AUTOSAR XML (schema 4-2-2)
standard types defined: boolean, float32, sint16, sint32, sint8, uint16, uint32, uint8
package /Communication/DataTransformation
  data transformation set TransformerChains
    data transformation TransformerChain_E2E_only: execute-despite-data-unavailability=true, transformer-chain=E2E_Transformer
    data transformation TransformerChain_SOME_IP_E2E: execute-despite-data-unavailability=true, transformer-chain=[SOME_IP_Transformer, E2E_Transformer]
    data transformation TransformerChain_SOME_IP_only: execute-despite-data-unavailability=true, transformer-chain=SOME_IP_Transformer
  data transformation set Transformers
    transformation technology E2E_Transformer: needs-original-data=false, protocol=E2E, transformer-class=SAFETY, version=1
    transformation technology SOME_IP_Transformer: protocol=SOMEIP, someip-transformation-description{alignment=8, byte-order=big-endian, interface-version=1}, transformer-class=SERIALIZER, version=1
package /Communication/Diagnostics
  diagnostic connection DoIP_MyECU: functional-request=DoIP_Conn_funct, physical-request=DoIP_Conn_MyECU_Physical_Request, response=DoIP_Conn_MyECU_Response
  diagnostic connection DoIP_MyECU_Flasher: functional-request=DoIP_Conn_funct_Flasher, physical-request=DoIP_Conn_MyECU_Physical_Request_Flasher, response=DoIP_Conn_MyECU_Response_Flasher
package /Communication/GlobalTimeSynchronization
  global time domain GlobalTimeDomain: communication-cluster=ETHCluster
    global time eth master MyECU_ETH_GlobalTimeMaster: communication-connector=MyECU_EEI_U, is-system-wide-global-time-master=true, sync-period=0.125
package /Communication/NetworkManagement
  nm config NM_CONFIG: udp-nm-cluster-coupling=coupled-cluster=NM_Cluster
    udp nm cluster NM_Cluster: communication-cluster=ETHCluster, nm-channel-id=48, nm-channel-active=true, nm-message-timeout-time=0.06, nm-msg-cycle-time=0.1, nm-network-timeout=1, nm-nid-position=1, nm-remote-sleep-indication-time=0.5, nm-repeat-message-time=0.4, nm-user-data-length=6, nm-wait-bus-sleep-time=0.75
      udp nm node MyECU_NM_Node: controller=BA_MyECU_0_EPC, nm-if-ecu=MyECU_NM_ECU, rx-nm-pdu=PDU_UdpNmRX_MyECU, tx-nm-pdu=PDU_UdpNmTx_MyECU
    nm-if-ecus:
      nm ecu MyECU_NM_ECU: ecu-instance=MyECU, nm-com-control-enabled=true, nm-node-id-enabled=true, nm-passive-mode-enabled=false, nm-user-data-enabled=true
package /Communication/PDUs
  dcm i pdu DoIP_MyECU_Physical_Request_Tester_MyECU: length=188
  dcm i pdu DoIP_MyECU_Physical_Request_Tester_MyECU_Flasher: length=188
  dcm i pdu DoIP_MyECU_Response_MyECU_Tester: length=188
  dcm i pdu DoIP_MyECU_Response_MyECU_Tester_Flasher: length=188
  dcm i pdu DoIP_Functional_Request_DoIP_Flasher: length=188
  dcm i pdu DoIP_Functional_Request_all_nodes: length=188
  general purpose pdu DoIP_TCP01_MyECU_Tx_Tester_Rx: category=DoIP, length=8
  general purpose pdu DoIP_TCP01_Tester_Tx_MyECU_Rx: category=DoIP, length=8
  general purpose pdu DoIP_TCP02_MyECU_Tx_Tester_Rx: category=DoIP, length=8
  general purpose pdu DoIP_TCP02_Tester_Tx_MyECU_Rx: category=DoIP, length=8
  general purpose pdu DoIP_UDP_MyECU_Tx_Tester_Rx: category=DoIP, length=8
  general purpose pdu DoIP_UDP_Tester_Tx_MyECU_Rx: category=DoIP, length=8
  general purpose pdu DoIP_UDP_VehicleAnnouncement: category=DoIP, length=8
  general purpose pdu SD_Ctrl_Rx: category=SD, length=1500
  general purpose pdu SD_Ctrl_Rx_Multicast: category=SD, length=1500
  general purpose pdu SD_Ctrl_Tx: category=SD, length=1500
  pdu Basics_Echo_Dashboard: length=12, transmission-mode-true-timing=event-controlled-timing=number-of-repetitions=0, unused-bit-pattern=0
    signal Basics_Echo_Dashboard: start 0, 96 bit, opaque, data-transformations=TransformerChain_SOME_IP_only, data-type-policy=OVERRIDE, base-type=LdCom_UINT8_N, someip-transformation-i-signal-props=SOME_IP_Transformer, transfer-property=TRIGGERED, to MyECU
  pdu Maths_Add_call_Dashboard: length=16, transmission-mode-true-timing=event-controlled-timing=number-of-repetitions=0, unused-bit-pattern=0
    signal Maths_Add_call_Dashboard: start 0, 128 bit, opaque, data-transformations=TransformerChain_SOME_IP_only, data-type-policy=OVERRIDE, base-type=LdCom_UINT8_N, someip-transformation-i-signal-props=SOME_IP_Transformer, transfer-property=TRIGGERED, to MyECU
  pdu Maths_Add_return_MyECU: length=12, transmission-mode-true-timing=event-controlled-timing=number-of-repetitions=0, unused-bit-pattern=0
    signal Maths_Add_return_MyECU: start 0, 96 bit, opaque, data-transformations=TransformerChain_SOME_IP_only, data-type-policy=OVERRIDE, base-type=LdCom_UINT8_N, someip-transformation-i-signal-props=SOME_IP_Transformer, transfer-property=TRIGGERED
  pdu Maths_Divide_call_Dashboard: length=16, transmission-mode-true-timing=event-controlled-timing=number-of-repetitions=0, unused-bit-pattern=0
    signal Maths_Divide_call_Dashboard: start 0, 128 bit, opaque, data-transformations=TransformerChain_SOME_IP_only, data-type-policy=OVERRIDE, base-type=LdCom_UINT8_N, someip-transformation-i-signal-props=SOME_IP_Transformer, transfer-property=TRIGGERED, to MyECU
  pdu Maths_Divide_return_MyECU: length=12, transmission-mode-true-timing=event-controlled-timing=number-of-repetitions=0, unused-bit-pattern=0
    signal Maths_Divide_return_MyECU: start 0, 96 bit, opaque, data-transformations=TransformerChain_SOME_IP_only, data-type-policy=OVERRIDE, base-type=LdCom_UINT8_N, someip-transformation-i-signal-props=SOME_IP_Transformer, transfer-property=TRIGGERED
  pdu Maths_Multiply_call_Dashboard: length=16, transmission-mode-true-timing=event-controlled-timing=number-of-repetitions=0, unused-bit-pattern=0
    signal Maths_Multiply_call_Dashboard: start 0, 128 bit, opaque, data-transformations=TransformerChain_SOME_IP_only, data-type-policy=OVERRIDE, base-type=LdCom_UINT8_N, someip-transformation-i-signal-props=SOME_IP_Transformer, transfer-property=TRIGGERED, to MyECU
  pdu Maths_Multiply_return_MyECU: length=12, transmission-mode-true-timing=event-controlled-timing=number-of-repetitions=0, unused-bit-pattern=0
    signal Maths_Multiply_return_MyECU: start 0, 96 bit, opaque, data-transformations=TransformerChain_SOME_IP_only, data-type-policy=OVERRIDE, base-type=LdCom_UINT8_N, someip-transformation-i-signal-props=SOME_IP_Transformer, transfer-property=TRIGGERED
  pdu Maths_Substract_call_Dashboard: length=16, transmission-mode-true-timing=event-controlled-timing=number-of-repetitions=0, unused-bit-pattern=0
    signal Maths_Substract_call_Dashboard: start 0, 128 bit, opaque, data-transformations=TransformerChain_SOME_IP_only, data-type-policy=OVERRIDE, base-type=LdCom_UINT8_N, someip-transformation-i-signal-props=SOME_IP_Transformer, transfer-property=TRIGGERED, to MyECU
  pdu Maths_Substract_return_MyECU: length=12, transmission-mode-true-timing=event-controlled-timing=number-of-repetitions=0, unused-bit-pattern=0
    signal Maths_Substract_return_MyECU: start 0, 96 bit, opaque, data-transformations=TransformerChain_SOME_IP_only, data-type-policy=OVERRIDE, base-type=LdCom_UINT8_N, someip-transformation-i-signal-props=SOME_IP_Transformer, transfer-property=TRIGGERED
  pdu Maths_Triangle_MyECU: length=12, transmission-mode-true-timing=event-controlled-timing=number-of-repetitions=0, unused-bit-pattern=0
    signal Maths_Triangle_MyECU: start 0, 96 bit, opaque, data-transformations=TransformerChain_SOME_IP_only, data-type-policy=OVERRIDE, base-type=LdCom_UINT8_N, someip-transformation-i-signal-props{transformer=SOME_IP_Transformer, message-type=NOTIFICATION}, transfer-property=TRIGGERED
  nm pdu PDU_UdpNmRX_MyECU: length=8, nm-data-information=true  # NM_Dummy_ST3 | Network Management
    signal S_UdpNm_UserData_Rx_MyECU: start 16, 48 bit, opaque, system signal SS_UdpNm_UserData_Rx, data-type-policy=OVERRIDE, init-value=\0, base-type=uint8_6_iso_8859_1, transfer-property=PENDING
  nm pdu PDU_UdpNmTx_MyECU: length=8, nm-data-information=true  # NM_BC_F_ST3 | Network Management
    signal S_UdpNm_UserData_Tx_MyECU: start 16, 48 bit, opaque, system signal SS_UdpNm_UserData_Tx, data-type-policy=OVERRIDE, init-value=6 x 0, base-type=uint8_6_iso_8859_1, transfer-property=PENDING
  xcp pdu XCP_Request_PDU: length=16
  xcp pdu XCP_Response_PDU: length=128
package /Communication/SystemSignals
  9 x system signal:
    Maths_1_Add_call
    Maths_1_Add_return
    Maths_1_Divide_call
    Maths_1_Divide_return
    Maths_1_Multiply_call
    Maths_1_Multiply_return
    Maths_1_Substract_call
    Maths_1_Substract_return
    Maths_1_Triangle
package /Communication/TransportProtocol
  do ip tp config DoIPCfg: communication-cluster=ETHCluster
    6 x do ip logic address:
      DoIP_SA_Flasher: address=1
      DoIP_SA_Tester: address=409
      DoIP_TA_MyECU: address=512
      DoIP_TA_MyECU_Flash: address=512
      DoIP_TA_funct: address=58368
      DoIP_TA_funct_Flash: address=58368
    do-ip-tp-connection do-ip-source-address=DoIP_SA_Flasher, do-ip-target-address=DoIP_TA_MyECU_Flash, tp-sdu=DoIP_MyECU_Physical_Request_Tester_MyECU_Flasher:
      ident DoIP_Conn_MyECU_Physical_Request_Flasher
    do-ip-tp-connection do-ip-source-address=DoIP_SA_Flasher, do-ip-target-address=DoIP_TA_funct_Flash, tp-sdu=DoIP_Functional_Request_DoIP_Flasher:
      ident DoIP_Conn_funct_Flasher
    do-ip-tp-connection do-ip-source-address=DoIP_SA_Tester, do-ip-target-address=DoIP_TA_MyECU, tp-sdu=DoIP_MyECU_Physical_Request_Tester_MyECU:
      ident DoIP_Conn_MyECU_Physical_Request
    do-ip-tp-connection do-ip-source-address=DoIP_SA_Tester, do-ip-target-address=DoIP_TA_funct, tp-sdu=DoIP_Functional_Request_all_nodes:
      ident DoIP_Conn_funct
    do-ip-tp-connection do-ip-source-address=DoIP_TA_MyECU, do-ip-target-address=DoIP_SA_Tester, tp-sdu=DoIP_MyECU_Response_MyECU_Tester:
      ident DoIP_Conn_MyECU_Response
    do-ip-tp-connection do-ip-source-address=DoIP_TA_MyECU_Flash, do-ip-target-address=DoIP_SA_Flasher, tp-sdu=DoIP_MyECU_Response_MyECU_Tester_Flasher:
      ident DoIP_Conn_MyECU_Response_Flasher
package /Constants
  constant specification InitValue_0: value-spec=0 0 0 0 0 0
  constant specification initValue_Array_int: value-spec=[Lit1:0, Lit2:0, Lit3:0, Lit4:0, Lit5:0, Lit6:0]
package /DataTypeMappingSets
  data type mapping set Data_Type_Mappings
    data-type-maps:
      application-data-type=REC_Basics_1_0_Echo, implementation-data-type=REC_Basics_1_0_Echo
      application-data-type=REC_Maths_1_0_Triangle, implementation-data-type=REC_Maths_1_0_Triangle
      application-data-type=boolean_DT, implementation-data-type=boolean
      application-data-type=float32_DT, implementation-data-type=float32
      application-data-type=int16_DT, implementation-data-type=sint16
      application-data-type=int32_DT, implementation-data-type=sint32
      application-data-type=int8_DT, implementation-data-type=sint8
      application-data-type=uint16_DT, implementation-data-type=uint16
      application-data-type=uint8_DT, implementation-data-type=uint8
package /DataTypes/ApplicationDataTypes
  16 x app type:
    AdminDataTextType: category=STRING
    Boolean: category=BOOLEAN
    Opaque: category=opaque
    Reference: category=REFERENCE
    SOMEIP_ID: category=VALUE
    SOMEIP_ServiceID: category=VALUE
    String: category=STRING
    boolean_DT: category=VALUE
    float32_ADT_Basics: category=VALUE
    float32_ADT_Triangle: category=VALUE
    float32_DT: category=VALUE
    int16_DT: category=VALUE
    int32_DT: category=VALUE
    int8_DT: category=VALUE
    uint16_DT: category=VALUE
    uint8_DT: category=VALUE
  application record data type REC_Basics_1_0_Echo: category=STRUCTURE
    application record element value: category=VALUE, type=float32_ADT_Basics
  application record data type REC_Maths_1_0_Triangle: category=STRUCTURE
    application record element sample: category=VALUE, type=float32_ADT_Triangle
package /DataTypes/BaseTypes
  5 x base type, all with category=FIXED_LENGTH:
    LdCom_UINT8_N: base-type-size=8, base-type-encoding=NONE
    UdpNm_UINT8_N: base-type-size=8, base-type-encoding=NONE, byte-order=opaque
    uint32_1: base-type-size=32, base-type-encoding=NONE
    uint8_6_iso_8859_1: base-type-size=48, base-type-encoding=ISO-8859-1
    uint8_8_iso_8859_1: base-type-size=64, base-type-encoding=ISO-8859-1
package /DataTypes/CompuMethods
  compu method CM_sig_VitaReq_Ctrl: 0..4294967295=RANGE
  compu method CM_sig_VitaReq_Data: 0..4294967295=RANGE
  compu method CM_sig_VitaResp_Ctrl: 0..4294967295=RANGE
  compu method CM_sig_VitaResp_Data: 0..4294967295=RANGE
  compu method CM_sig_com_data1_CAN1: 0..18446744073709551615=RANGE
  compu method CM_sig_com_data1_CAN2: 0..18446744073709551615=RANGE
  compu method CM_sig_com_data2_CAN1: 0..18446744073709551615=RANGE
  compu method CM_sig_com_data2_CAN2: 0..18446744073709551615=RANGE
  compu method CM_sig_nm_MyECU_CAN1_UserData: 0..281474976710655=RANGE
  compu method CM_sig_nm_MyECU_CAN2_UserData: 0..281474976710655=RANGE
package /DataTypes/ImplementationDataTypes
  6 x impl type, all with category=STRUCTURE:
    REC_Basics_1_0_Echo
      element float32_Basics: category=VALUE, base-type=float32
    REC_BatteryWarning
      element boolean_BatteryWarning: category=VALUE, base-type=boolean, compu {0=FALSE, 1=TRUE}
    REC_Maths_1_0_Triangle
      element float32_Triangle: category=VALUE, base-type=float32
    REC_TurnIndicationSig
      element boolean_Turnindication: category=VALUE, base-type=boolean, compu {0=Blinker_OFF, 1=Blinker_ON}
    REC_Volume_1_0_CurrentFrequency
      element uint16_Frequency: category=VALUE, base-type=uint16
    REC_Volume_1_0_CurrentVolume
      element uint8_Volume: category=VALUE, base-type=uint8
package /SoAdRoutingGroups
  so ad routing group Basics_events: event-group-control-type=ACTIVATION-UNICAST
  so ad routing group Math_events: event-group-control-type=ACTIVATION-AND-TRIGGER-UNICAST
  so ad routing group Math_methods
package /SoftwareTypes/ComponentTypes
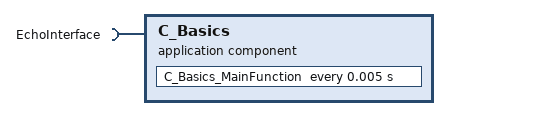
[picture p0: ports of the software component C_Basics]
  application sw component type C_Basics
    require port EchoInterface: nonqueued-receiver-com-spec{data-element=Echo, max-delta-counter-init=-1, filter=data-filter-type=ALWAYS, init-value=fields=0}, required-interface=EchoInterface
    behavior C_Basics_ib: data-type-mapping=Data_Type_Mappings
      timing event TMT_C_Basics_MainFunction: start-on-event=C_Basics_MainFunction, period=0.005
      runnable C_Basics_MainFunction
        data-receive-point-by-arguments:
          access REC_EchoInterface_Echo: accessed-variable=EchoInterface.Echo
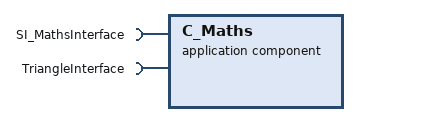
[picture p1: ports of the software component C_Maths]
  application sw component type C_Maths
    require port SI_MathsInterface: required-interface=SI_MathsInterface
    require port TriangleInterface: nonqueued-receiver-com-spec{data-element=Triangle, init-value=fields=0}, required-interface=TriangleInterface
    behavior C_Maths_ib: data-type-mapping=Data_Type_Mappings
  application sw component type P_Basics
    provide port EchoInterface: provided-interface=EchoInterface
    behavior P_Basics_ib: data-type-mapping=Data_Type_Mappings
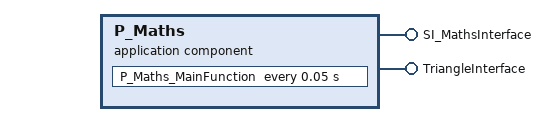
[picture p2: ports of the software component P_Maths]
  application sw component type P_Maths
    provide port SI_MathsInterface: provided-interface=SI_MathsInterface
      provided-com-specs:
        operation=Add, queue-length=1
        operation=Divide, queue-length=1
        operation=Multiply, queue-length=1
        operation=Substract, queue-length=1
    provide port TriangleInterface: nonqueued-sender-com-spec{data-element=Triangle, init-value=fields=0}, provided-interface=TriangleInterface
    behavior P_Maths_ib: data-type-mapping=Data_Type_Mappings
      4 x operation invoked event:
        OIT_P_Maths_SI_MathsInterface_Add_SI_MathsInterface_Add: start-on-event=P_Maths_SI_MathsInterface_Add, operation=SI_MathsInterface.Add
        OIT_P_Maths_SI_MathsInterface_Divide_SI_MathsInterface_Divide: start-on-event=P_Maths_SI_MathsInterface_Divide, operation=SI_MathsInterface.Divide
        OIT_P_Maths_SI_MathsInterface_Multiply_SI_MathsInterface_Multiply: start-on-event=P_Maths_SI_MathsInterface_Multiply, operation=SI_MathsInterface.Multiply
        OIT_P_Maths_SI_MathsInterface_Substract_SI_MathsInterface_Substract: start-on-event=P_Maths_SI_MathsInterface_Substract, operation=SI_MathsInterface.Substract
      timing event TMT_P_Maths_MainFunction: start-on-event=P_Maths_MainFunction, period=0.05
      5 x runnable:
        P_Maths_MainFunction
          data-send-points:
            access SEND_TriangleInterface_Triangle: accessed-variable=TriangleInterface.Triangle
        P_Maths_SI_MathsInterface_Add
        P_Maths_SI_MathsInterface_Divide
        P_Maths_SI_MathsInterface_Multiply
        P_Maths_SI_MathsInterface_Substract
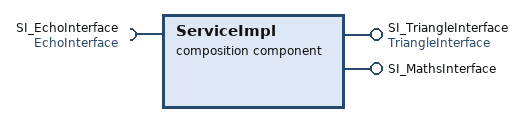
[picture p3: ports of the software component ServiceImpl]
  composition sw component type ServiceImpl
    require port SI_EchoInterface: nonqueued-receiver-com-spec{data-element=Echo, max-delta-counter-init=-1, filter=data-filter-type=ALWAYS}, required-interface=EchoInterface
    provide port SI_TriangleInterface: nonqueued-sender-com-spec=Triangle, provided-interface=TriangleInterface
    provide port SI_MathsInterface: provided-interface=SI_MathsInterface
      provided-com-specs:
        operation=Add, queue-length=1
        operation=Divide, queue-length=1
        operation=Multiply, queue-length=1
        operation=Substract, queue-length=1
    component C_Basics_MyECU: type=C_Basics
    component P_Maths_MyECU: type=P_Maths
    delegate P_Maths_MyECU.TriangleInterface <-> outer port ServiceImpl/SI_TriangleInterface
    delegate C_Basics_MyECU.EchoInterface <-> outer port ServiceImpl/SI_EchoInterface
    delegate P_Maths_MyECU.SI_MathsInterface <-> outer port ServiceImpl/SI_MathsInterface
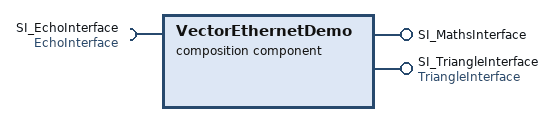
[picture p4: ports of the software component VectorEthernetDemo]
  composition sw component type VectorEthernetDemo
    provide port SI_MathsInterface: provided-interface=SI_MathsInterface
      provided-com-specs:
        operation=Add, queue-length=1
        operation=Divide, queue-length=1
        operation=Multiply, queue-length=1
        operation=Substract, queue-length=1
    provide port SI_TriangleInterface: nonqueued-sender-com-spec=Triangle, provided-interface=TriangleInterface
    require port SI_EchoInterface: nonqueued-receiver-com-spec{data-element=Echo, max-delta-counter-init=-1, filter=data-filter-type=ALWAYS}, required-interface=EchoInterface
    component ServiceImpl: type=ServiceImpl
    delegate ServiceImpl.SI_TriangleInterface <-> outer port VectorEthernetDemo/SI_TriangleInterface
    delegate ServiceImpl.SI_MathsInterface <-> outer port VectorEthernetDemo/SI_MathsInterface
    delegate ServiceImpl.SI_EchoInterface <-> outer port VectorEthernetDemo/SI_EchoInterface
package /SoftwareTypes/Interfaces
  client server interface SI_MathsInterface
    4 x operation:
      Add
        arg operand1: type=int32_DT, direction=IN, server-argument-impl-policy=USE-ARGUMENT-TYPE
        arg operand2: type=int32_DT, direction=IN, server-argument-impl-policy=USE-ARGUMENT-TYPE
        arg result: type=float32_DT, direction=OUT, server-argument-impl-policy=USE-ARGUMENT-TYPE
      Divide: possible-error=E_DIVISION_BY_ZERO
        arg operand1: type=int32_DT, direction=IN, server-argument-impl-policy=USE-ARGUMENT-TYPE
        arg operand2: type=int32_DT, direction=IN, server-argument-impl-policy=USE-ARGUMENT-TYPE
        arg result: type=float32_DT, direction=OUT, server-argument-impl-policy=USE-ARGUMENT-TYPE
      Multiply
        arg operand1: type=int32_DT, direction=IN, server-argument-impl-policy=USE-ARGUMENT-TYPE
        arg operand2: type=int32_DT, direction=IN, server-argument-impl-policy=USE-ARGUMENT-TYPE
        arg result: type=float32_DT, direction=OUT, server-argument-impl-policy=USE-ARGUMENT-TYPE
      Substract
        arg operand1: type=int32_DT, direction=IN, server-argument-impl-policy=USE-ARGUMENT-TYPE
        arg operand2: type=int32_DT, direction=IN, server-argument-impl-policy=USE-ARGUMENT-TYPE
        arg result: type=float32_DT, direction=OUT, server-argument-impl-policy=USE-ARGUMENT-TYPE
    error E_DIVISION_BY_ZERO: error-code=1
  sender receiver interface EchoInterface: invalidation-policy{data-element=Echo, handle-invalid=DONT-INVALIDATE}
    data Echo: type=REC_Basics_1_0_Echo
  sender receiver interface TriangleInterface: invalidation-policy{data-element=Triangle, handle-invalid=DONT-INVALIDATE}
    data Triangle: type=REC_Maths_1_0_Triangle
package /System
  system VectorEthernetDemo
    system mapping Mappings
      data-mappings:
        client-server-to-signal-mapping={call-signal=Maths_Add_call, client-server-operation=VectorEthernetDemo.ServiceImpl.P_Maths_MyECU.SI_MathsInterface.Add, return-signal=Maths_Add_return}
        client-server-to-signal-mapping={call-signal=Maths_Divide_call, client-server-operation=VectorEthernetDemo.ServiceImpl.P_Maths_MyECU.SI_MathsInterface.Divide, return-signal=Maths_Divide_return}
        client-server-to-signal-mapping={call-signal=Maths_Multiply_call, client-server-operation=VectorEthernetDemo.ServiceImpl.P_Maths_MyECU.SI_MathsInterface.Multiply, return-signal=Maths_Multiply_return}
        client-server-to-signal-mapping={call-signal=Maths_Substract_call, client-server-operation=VectorEthernetDemo.ServiceImpl.P_Maths_MyECU.SI_MathsInterface.Substract, return-signal=Maths_Substract_return}
        sender-receiver-to-signal-mapping={data-element=ServiceImpl.C_Basics_MyECU.VectorEthernetDemo.EchoInterface.Echo, system-signal=Basics_Echo}
        sender-receiver-to-signal-mapping={data-element=ServiceImpl.P_Maths_MyECU.VectorEthernetDemo.TriangleInterface.Triangle, system-signal=Maths_Triangle}
      sw-mappings:
        swc to ecu mapping SW_NET_Component_Mapping358: component=VectorEthernetDemo.ServiceImpl.P_Maths_MyECU, ecu-instance=MyECU
        swc to ecu mapping SW_NET_Component_Mapping361: component=VectorEthernetDemo.ServiceImpl.C_Basics_MyECU, ecu-instance=MyECU
    root-software-compositions:
      root sw composition prototype VectorEthernetDemo: software-composition=VectorEthernetDemo
package /Topology/Clusters
  ethernet cluster ETHCluster
    ethernet physical channel NM: comm-connectors=MyECU_EEI_V10_NM
      pdu triggering PT_UdpNmRx_MyECU: pdu=PDU_UdpNmRX_MyECU, to MyECU
      pdu triggering PT_UdpNmTx_MyECU: pdu=PDU_UdpNmTx_MyECU, from MyECU
      network endpoint NEP_IPv6_ANY: network-endpoint-addresses=ipv-6-configuration={assignment-priority=1, hop-count=0, ip-address-prefix-length=64}
      network endpoint NEP_NM_IPv6_MyECU_LinkLocal: network-endpoint-addresses=ipv-6-configuration={assignment-priority=1, hop-count=0, ip-address-keep-behavior=FORGET, ip-address-prefix-length=10, ipv-6-address-source=LINK-LOCAL}
      network endpoint NEP_NM_IPv6_Multicast: network-endpoint-addresses=ipv-6-configuration={assignment-priority=1, hop-count=0, ip-address-keep-behavior=STORE-PERSISTENTLY, ipv-6-address=FF02:0:0:0:0:0:0:1, ipv-6-address-source=FIXED}
      so-ad-config:
        socket connection bundle SCB_NM_MyECU: socket-connection{client-port=NM_IPv6_ANY, pdus=socket-connection-ipdu-identifier=PT_UdpNmTx_MyECU, socket-protocol=UDP}, server-port=NM_IPv6_MyECU
        socket connection bundle SCB_NM_Global: socket-connection{client-port=NM_IPv6_ANY, pdus=socket-connection-ipdu-identifier=PT_UdpNmRx_MyECU, socket-protocol=UDP}, server-port=NM_IPv6_Multicast
        socket address NM_IPv6_MyECU: connector=MyECU_EEI_V10_NM
          application endpoint AEP_NM_MyECU: network-endpoint=NEP_NM_IPv6_MyECU_LinkLocal, tp-configuration=udp-tp=udp-tp-port=port-number=1001
        socket address NM_IPv6_ANY
          application endpoint AEP_NM_ANY: network-endpoint=NEP_IPv6_ANY, tp-configuration=udp-tp=udp-tp-port=port-number=1001
        socket address NM_IPv6_Multicast: multicast-connector=MyECU_EEI_V10_NM
          application endpoint AEP_NM_Multicast: network-endpoint=NEP_NM_IPv6_Multicast, tp-configuration=udp-tp=udp-tp-port=port-number=1001
      vlan NM: vlan-identifier=10
    ethernet physical channel untaggedTraffic: comm-connectors=MyECU_EEI_U
      pdu triggering Basics_Echo_Dashboard_1: pdu=Basics_Echo_Dashboard, to MyECU
      pdu triggering DoIP_MyECU_Physical_Request_Tester_MyECU: pdu=DoIP_MyECU_Physical_Request_Tester_MyECU, to MyECU
      pdu triggering DoIP_MyECU_Physical_Request_Tester_MyECU_Flasher: pdu=DoIP_MyECU_Physical_Request_Tester_MyECU_Flasher, to MyECU
      pdu triggering DoIP_MyECU_Response_MyECU_Tester: pdu=DoIP_MyECU_Response_MyECU_Tester, from MyECU
      pdu triggering DoIP_MyECU_Response_MyECU_Tester_Flasher: pdu=DoIP_MyECU_Response_MyECU_Tester_Flasher, from MyECU
      pdu triggering DoIP_Functional_Request_DoIP_Flasher: pdu=DoIP_Functional_Request_DoIP_Flasher, to MyECU
      pdu triggering DoIP_Functional_Request_all_nodes: pdu=DoIP_Functional_Request_all_nodes, to MyECU
      pdu triggering DoIP_TCP01_MyECU_Tx_Tester_Rx: pdu=DoIP_TCP01_MyECU_Tx_Tester_Rx, from MyECU
      pdu triggering DoIP_TCP01_Tester_Tx_MyECU_Rx: pdu=DoIP_TCP01_Tester_Tx_MyECU_Rx, to MyECU
      pdu triggering DoIP_TCP02_MyECU_Tx_Tester_Rx: pdu=DoIP_TCP02_MyECU_Tx_Tester_Rx, from MyECU
      pdu triggering DoIP_TCP02_Tester_Tx_MyECU_Rx: pdu=DoIP_TCP02_Tester_Tx_MyECU_Rx, to MyECU
      pdu triggering DoIP_UDP_MyECU_Tx_Tester_Rx: pdu=DoIP_UDP_MyECU_Tx_Tester_Rx, from MyECU
      pdu triggering DoIP_UDP_Tester_Tx_MyECU_Rx: pdu=DoIP_UDP_Tester_Tx_MyECU_Rx, to MyECU
      pdu triggering DoIP_UDP_VehicleAnnouncement: pdu=DoIP_UDP_VehicleAnnouncement, from MyECU
      pdu triggering Maths_Add_call_Dashboard_1: pdu=Maths_Add_call_Dashboard, to MyECU
      pdu triggering Maths_Add_return_MyECU_1: pdu=Maths_Add_return_MyECU, from MyECU
      pdu triggering Maths_Divide_call_Dashboard_1: pdu=Maths_Divide_call_Dashboard, to MyECU
      pdu triggering Maths_Divide_return_MyECU_1: pdu=Maths_Divide_return_MyECU, from MyECU
      pdu triggering Maths_Multiply_call_Dashboard_1: pdu=Maths_Multiply_call_Dashboard, to MyECU
      pdu triggering Maths_Multiply_return_MyECU_1: pdu=Maths_Multiply_return_MyECU, from MyECU
      pdu triggering Maths_Substract_call_Dashboard_1: pdu=Maths_Substract_call_Dashboard, to MyECU
      pdu triggering Maths_Substract_return_MyECU_1: pdu=Maths_Substract_return_MyECU, from MyECU
      pdu triggering Maths_Triangle_MyECU_1: pdu=Maths_Triangle_MyECU, from MyECU
      pdu triggering SD_Ctrl_Rx_MyECU: pdu=SD_Ctrl_Rx, to MyECU
      pdu triggering SD_Ctrl_Rx_Multicast_MyECU: pdu=SD_Ctrl_Rx_Multicast, to MyECU
      pdu triggering SD_Ctrl_Tx_MyECU: pdu=SD_Ctrl_Tx, from MyECU
      pdu triggering XCP_Request: pdu=XCP_Request_PDU, to MyECU
      pdu triggering XCP_Response: pdu=XCP_Response_PDU, from MyECU
      11 x network endpoint:
        BC_Terminal_DoIP_NEP
        NEP_ANY: network-endpoint-addresses=ipv-4-configuration={assignment-priority=1, ttl=0}
        NEP_AppServer: network-endpoint-addresses=ipv-4-configuration={assignment-priority=1, ipv-4-address=192.168.1.30, ipv-4-address-source=FIXED, ttl=0}
        NEP_BMS: network-endpoint-addresses=ipv-4-configuration={assignment-priority=1, ipv-4-address=192.168.1.13, ipv-4-address-source=FIXED, ttl=0}
        NEP_CAN_SD_Multicast: network-endpoint-addresses=ipv-4-configuration={assignment-priority=1, ipv-4-address=224.168.10.0}
        NEP_MyECU: network-endpoint-addresses=ipv-4-configuration={assignment-priority=1, ipv-4-address=192.168.1.11, ipv-4-address-source=FIXED, network-mask=255.255.255.0, ttl=0}
        NEP_CanEthRouting: network-endpoint-addresses=ipv-4-configuration=ipv-4-address=224.168.1.0
        NEP_Dashboard: network-endpoint-addresses=ipv-4-configuration={assignment-priority=1, ipv-4-address=192.168.1.10, ipv-4-address-source=FIXED, ttl=0}
        NEP_HeadUnit: network-endpoint-addresses=ipv-4-configuration={assignment-priority=1, ipv-4-address=192.168.1.12, ipv-4-address-source=FIXED, ttl=0}
        NEP_IPv4_Broadcast: network-endpoint-addresses=ipv-4-configuration=ipv-4-address=255.255.255.255
        NEP_SD_Multicast_IP: network-endpoint-addresses=ipv-4-configuration={assignment-priority=1, ipv-4-address=239.192.255.251, ipv-4-address-source=FIXED, ttl=0}
      so-ad-config:
        8 x socket connection bundle:
          SCB_Xcp_MyECU: socket-connection{client-port=SA_ANY_XCP, pdus=[XCP_Request, XCP_Response], socket-protocol=UDP}, server-port=MyECU_Xcp
          SD_Multi_MyECU: socket-connection{client-port=SA_ANY, pdus=socket-connection-ipdu-identifier={header-id=4294934784, pdu-triggering=SD_Ctrl_Rx_Multicast_MyECU}, socket-protocol=UDP}, server-port=SD_Multicast
          SCB_DoIP_TCP: server-port=MyECU_DoIP_TCP
            bundled-connections:
              client-port=DoIP_TCP_ANY, pdus=[DoIP_TCP01_MyECU_Tx_Tester_Rx, DoIP_TCP01_Tester_Tx_MyECU_Rx]
              client-port=DoIP_TCP_ANY, pdus=[DoIP_TCP02_MyECU_Tx_Tester_Rx, DoIP_TCP02_Tester_Tx_MyECU_Rx]
          SCB_DoIP_UDP: server-port=MyECU_DoIP_UDP
            bundled-connections:
              client-port=DoIP_UDP_ANY, pdus=[DoIP_UDP_MyECU_Tx_Tester_Rx, DoIP_UDP_Tester_Tx_MyECU_Rx], socket-protocol=UDP
              client-port=DoIP_UDP_Broadcast, pdus=socket-connection-ipdu-identifier=DoIP_UDP_VehicleAnnouncement, socket-protocol=UDP
          SCB_Math:
            socket-connection{client-port=ANY_Maths, pdus=[{header-id=720927, pdu-triggering=Maths_Add_call_Dashboard_1, routing-group=Math_methods}, {header-id=720927, pdu-triggering=Maths_Add_return_MyECU_1, routing-group=Math_methods}, {header-id=720928, pdu-triggering=Maths_Substract_call_Dashboard_1, routing-group=Math_methods}, {header-id=720928, pdu-triggering=Maths_Substract_return_MyECU_1, routing-group=Math_methods}, {header-id=720929, pdu-triggering=Maths_Multiply_call_Dashboard_1, routing-group=Math_methods}, {header-id=720929, pdu-triggering=Maths_Multiply_return_MyECU_1, routing-group=Math_methods}, {header-id=720930, pdu-triggering=Maths_Divide_call_Dashboard_1, routing-group=Math_methods}, {header-id=720930, pdu-triggering=Maths_Divide_return_MyECU_1, routing-group=Math_methods}]}
            pdus=socket-connection-ipdu-identifier={header-id=753665, pdu-triggering=Maths_Triangle_MyECU_1, routing-group=Math_events}
            server-port=MyECU_Maths
          SD_Uni_MyECU: socket-connection{client-port=SA_ANY, pdus=[{header-id=4294934784, pdu-triggering=SD_Ctrl_Rx_MyECU}, {header-id=4294934784, pdu-triggering=SD_Ctrl_Tx_MyECU}], socket-protocol=UDP}, server-port=SD_Unicast_MyECU
          SD_Uni: socket-connection{client-port=SA_ANY, socket-protocol=UDP}, server-port=SD_Unicast
          SCB_Basics: socket-connection{client-port=MyECU_Basics, socket-protocol=UDP}, pdus=socket-connection-ipdu-identifier={header-id=688129, pdu-triggering=Basics_Echo_Dashboard_1, routing-group=Basics_events}, server-port=ANY_Basics
        17 x socket address:
          MyECU_Basics: connector=MyECU_EEI_U
            application endpoint BA_MyECU_0_EEI: network-endpoint=NEP_MyECU, tp-configuration=udp-tp=udp-tp-port=port-number=30501
              consumed service instance CSI_Basics: provided-service-instance=PSI_Basics, sd-client-config={client-service-major-version=1, client-service-minor-version=0, initial-find-behavior={initial-delay-max-value=0.5, initial-delay-min-value=0.1, initial-repetitions-base-delay=1.5, initial-repetitions-max=6}, ttl=5}
                consumed event group CEG_Basics: application-endpoint=MyECU_Basics/BA_MyECU_0_EEI, event-group-identifier=1, routing-group=Basics_events, sd-client-config={client-service-major-version=1, client-service-minor-version=0, request-response-delay={max-value=0.2, min-value=0.02}, ttl=5}
          MyECU_DoIP_TCP: connector=MyECU_EEI_U
            application endpoint MyECU_EEI_U: network-endpoint=NEP_MyECU, tp-configuration=tcp-tp=tcp-tp-port=port-number=13400
          MyECU_DoIP_UDP: connector=MyECU_EEI_U
            application endpoint MyECU_EEI_U: network-endpoint=NEP_MyECU, tp-configuration=udp-tp=udp-tp-port=port-number=13400
          MyECU_Maths: connector=MyECU_EEI_U
            application endpoint BA_MyECU_0_EEI: network-endpoint=NEP_MyECU, tp-configuration=udp-tp=udp-tp-port=port-number=30491
              provided service instance PSI_Maths: routing-group=Math_methods, instance-identifier=2, sd-server-config={initial-offer-behavior={initial-delay-max-value=2, initial-delay-min-value=0.5, initial-repetitions-base-delay=0.2, initial-repetitions-max=4}, offer-cyclic-delay=2, request-response-delay={max-value=1, min-value=0.1}, server-service-major-version=1, server-service-minor-version=0, ttl=3}, service-identifier=11
                event handler EH_Maths: consumed-event-group=CEG_Maths_Triangle, multicast-threshold=0, routing-group=Math_events, sd-server-config={request-response-delay={max-value=1, min-value=0.1}, server-service-major-version=1, server-service-minor-version=0, ttl=3}
          MyECU_Xcp: connector=MyECU_EEI_U
            application endpoint BA_MyECU_0_EEI: network-endpoint=NEP_MyECU, tp-configuration=udp-tp=udp-tp-port=port-number=5555
          CanEthRouting_Multicast
            application endpoint AEP: network-endpoint=NEP_CanEthRouting, tp-configuration=udp-tp=udp-tp-port=port-number=1234
          DoIP_TCP_ANY
            application endpoint AEP: network-endpoint=NEP_ANY, tp-configuration=tcp-tp=tcp-tp-port=port-number=0
          DoIP_UDP_ANY
            application endpoint AEP: network-endpoint=NEP_ANY, tp-configuration=udp-tp=udp-tp-port=port-number=0
          DoIP_UDP_Broadcast
            application endpoint AEP: network-endpoint=NEP_IPv4_Broadcast, tp-configuration=udp-tp=udp-tp-port=port-number=13400
          Multicast_Addr
            application endpoint AEP: network-endpoint=NEP_CAN_SD_Multicast, tp-configuration=udp-tp=udp-tp-port=port-number=4711
          SA_ANY
            application endpoint AEP: network-endpoint=NEP_ANY, tp-configuration=udp-tp=udp-tp-port=port-number=30490
          SD_Multicast: multicast-connector=MyECU_EEI_U
            application endpoint AEP: network-endpoint=NEP_SD_Multicast_IP, tp-configuration=udp-tp=udp-tp-port=port-number=30490
          SD_Unicast
            application endpoint BA_AppServer_0_EEI: network-endpoint=NEP_AppServer, tp-configuration=udp-tp=udp-tp-port=port-number=30490
          SD_Unicast_MyECU: connector=MyECU_EEI_U
            application endpoint BA_MyECU_0_EEI: network-endpoint=NEP_MyECU, tp-configuration=udp-tp=udp-tp-port=port-number=30490
          ANY_Basics
            application endpoint AEP_Basics_ANY: network-endpoint=NEP_ANY, tp-configuration=udp-tp=udp-tp-port=port-number=30501
              provided service instance PSI_Basics: instance-identifier=1, service-identifier=10
                event handler EH_Basics: consumed-event-group=CEG_Basics, multicast-threshold=0, routing-group=Basics_events
          SA_ANY_XCP
            application endpoint AEP_XCP: network-endpoint=NEP_ANY, tp-configuration=udp-tp=udp-tp-port=port-number=0
          ANY_Maths
            application endpoint AEP_Maths_ANY: network-endpoint=NEP_ANY, tp-configuration=udp-tp=udp-tp-port=port-number=30491
              consumed service instance CSI_Maths: provided-service-instance=PSI_Maths
                consumed event group CEG_Maths_Triangle: event-group-identifier=3, routing-group=Math_events
    mac multicast group MulticastMacAddress78: mac-multicast-address=01:00:5E:40:FF:FB
package /Topology/HardwareComponents
  ecu instance MyECU
    ethernet communication controller BA_MyECU_0_EPC: mac-unicast-address=AA:BB:CC:DD:00:0B
      coupling port BC_MyECU: connection-negotiation-behavior=SLAVE, coupling-port-speed=0, physical-layer-type=X-MMI, vlan-memberships=[{default-priority=2, vlan=NM}, {default-priority=0, vlan=untaggedTraffic}]
    ethernet communication connector MyECU_EEI_U: comm-controller=BA_MyECU_0_EPC, network-endpoint=[NEP_CAN_SD_Multicast, NEP_MyECU, NEP_SD_Multicast_IP]
    ethernet communication connector MyECU_EEI_V10_NM: comm-controller=BA_MyECU_0_EPC, network-endpoint=[NEP_NM_IPv6_MyECU_LinkLocal, NEP_NM_IPv6_Multicast]
